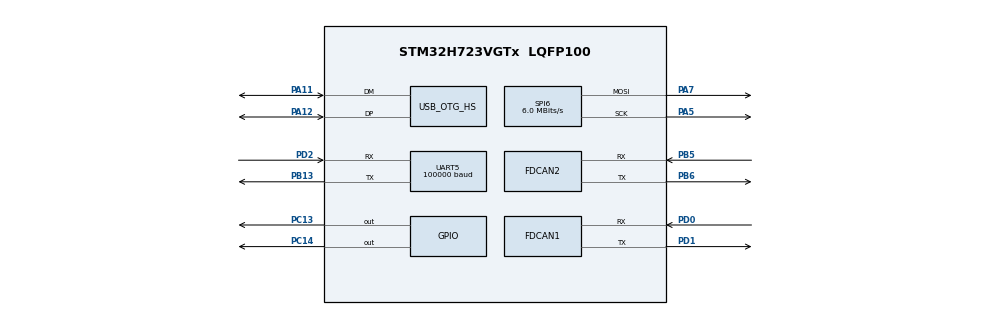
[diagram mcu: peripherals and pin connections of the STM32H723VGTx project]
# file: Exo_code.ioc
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CORTEX_M7.default_mode_Activation=0
Dma.Request0=UART5_RX
Dma.UART5_RX.0.Direction=DMA_PERIPH_TO_MEMORY
Dma.UART5_RX.0.EventEnable=DISABLE
Dma.UART5_RX.0.FIFOMode=DMA_FIFOMODE_DISABLE
Dma.UART5_RX.0.Instance=DMA1_Stream0
Dma.UART5_RX.0.MemDataAlignment=DMA_MDATAALIGN_BYTE
Dma.UART5_RX.0.MemInc=DMA_MINC_ENABLE
Dma.UART5_RX.0.Mode=DMA_CIRCULAR
Dma.UART5_RX.0.PeriphDataAlignment=DMA_PDATAALIGN_BYTE
Dma.UART5_RX.0.PeriphInc=DMA_PINC_DISABLE
Dma.UART5_RX.0.Polarity=HAL_DMAMUX_REQ_GEN_RISING
Dma.UART5_RX.0.Priority=DMA_PRIORITY_VERY_HIGH
Dma.UART5_RX.0.RequestNumber=1
Dma.UART5_RX.0.SignalID=NONE
Dma.UART5_RX.0.SyncEnable=DISABLE
Dma.UART5_RX.0.SyncPolarity=HAL_DMAMUX_SYNC_NO_EVENT
Dma.UART5_RX.0.SyncRequestNumber=1
Dma.UART5_RX.0.SyncSignalID=NONE
FDCAN1.CalculateBaudRateNominal=1000000
FDCAN1.CalculateTimeBitNominal=1000
FDCAN1.CalculateTimeQuantumNominal=25.0
FDCAN1.DataPrescaler=3
FDCAN1.DataSyncJumpWidth=10
FDCAN1.DataTimeSeg1=29
FDCAN1.DataTimeSeg2=10
FDCAN1.NominalPrescaler=3
FDCAN1.NominalSyncJumpWidth=10
FDCAN1.NominalTimeSeg1=29
FDCAN1.NominalTimeSeg2=10
FDCAN1.RxFifo0ElmtSize=FDCAN_DATA_BYTES_32
FDCAN1.RxFifo0ElmtsNbr=4
FDCAN1.StdFiltersNbr=1
FDCAN1.TxElmtSize=FDCAN_DATA_BYTES_32
FDCAN1.TxFifoQueueElmtsNbr=3
FDCAN2.CalculateBaudRateNominal=1000000
FDCAN2.CalculateTimeBitNominal=1000
FDCAN2.CalculateTimeQuantumNominal=25.0
FDCAN2.DataPrescaler=3
FDCAN2.DataSyncJumpWidth=10
FDCAN2.DataTimeSeg1=29
FDCAN2.DataTimeSeg2=10
FDCAN2.MessageRAMOffset=1280
FDCAN2.NominalPrescaler=3
FDCAN2.NominalSyncJumpWidth=10
FDCAN2.NominalTimeSeg1=29
FDCAN2.NominalTimeSeg2=10
FDCAN2.RxFifo0ElmtSize=FDCAN_DATA_BYTES_32
FDCAN2.RxFifo0ElmtsNbr=4
FDCAN2.RxFifo1ElmtSize=FDCAN_DATA_BYTES_8
FDCAN2.RxFifo1ElmtsNbr=0
FDCAN2.StdFiltersNbr=1
FDCAN2.TxElmtSize=FDCAN_DATA_BYTES_32
FDCAN2.TxFifoQueueElmtsNbr=3
FREERTOS.Tasks01=NMotor_Task,3,256,Motor_Task,As weak,NULL,Dynamic,NULL,NULL;NExo_Task,3,256,Exo_Task,As weak,NULL,Dynamic,NULL,NULL;NVofa_Task,3,256,Vofa_Task,As weak,NULL,Dynamic,NULL,NULL;NLed_Task,2,256,Led_Task,As weak,NULL,Dynamic,NULL,NULL
Mcu.Family=STM32H7
Mcu.Name=STM32H723VGTx
Mcu.Package=LQFP100
NVIC.DMA1_Stream0_IRQn=true\:5\:0\:false\:false\:true\:true\:false\:true\:true
NVIC.FDCAN1_IT0_IRQn=true\:5\:0\:false\:false\:true\:true\:true\:true\:true
NVIC.FDCAN2_IT0_IRQn=true\:5\:0\:false\:false\:true\:true\:true\:true\:true
NVIC.OTG_HS_IRQn=true\:5\:0\:false\:false\:true\:true\:true\:true\:true
NVIC.PriorityGroup=NVIC_PRIORITYGROUP_4
NVIC.TIM2_IRQn=true\:15\:0\:false\:false\:true\:false\:false\:true\:true
NVIC.TimeBase=TIM2_IRQn
NVIC.TimeBaseIP=TIM2
NVIC.UART5_IRQn=true\:5\:0\:false\:false\:true\:true\:true\:true\:true
PA11.Mode=Device_Only_FS
PA11.Signal=USB_OTG_HS_DM
PA12.Mode=Device_Only_FS
PA12.Signal=USB_OTG_HS_DP
PA13(JTMS/SWDIO).Mode=Serial_Wire
PA13(JTMS/SWDIO).Signal=DEBUG_JTMS-SWDIO
PA14(JTCK/SWCLK).Mode=Serial_Wire
PA14(JTCK/SWCLK).Signal=DEBUG_JTCK-SWCLK
PA5.GPIO_Speed=GPIO_SPEED_FREQ_VERY_HIGH
PA5.Mode=TX_Only_Simplex_Unidirect_Master
PA5.Signal=SPI6_SCK
PA7.GPIO_Speed=GPIO_SPEED_FREQ_VERY_HIGH
PA7.Mode=TX_Only_Simplex_Unidirect_Master
PA7.Signal=SPI6_MOSI
PB13.Mode=Asynchronous
PB13.Signal=UART5_TX
PB5.Mode=FDCAN_Activate
PB5.Signal=FDCAN2_RX
PB6.Mode=FDCAN_Activate
PB6.Signal=FDCAN2_TX
PC13.PinState=GPIO_PIN_SET
PC13.Signal=GPIO_Output
PC14-OSC32_IN.PinState=GPIO_PIN_SET
PC14-OSC32_IN.Signal=GPIO_Output
PD0.Mode=FDCAN_Activate
PD0.Signal=FDCAN1_RX
PD1.Mode=FDCAN_Activate
PD1.Signal=FDCAN1_TX
PD2.Mode=Asynchronous
PD2.Signal=UART5_RX
PH0-OSC_IN.Mode=HSE-External-Oscillator
PH0-OSC_IN.Signal=RCC_OSC_IN
PH1-OSC_OUT.Mode=HSE-External-Oscillator
PH1-OSC_OUT.Signal=RCC_OSC_OUT
ProjectManager.HeapSize=0x2000
ProjectManager.StackSize=0x4000
ProjectManager.TargetToolchain=CMake
RCC.ADCFreq_Value=48375000
RCC.APB1Freq_Value=120000000
RCC.APB2Freq_Value=120000000
RCC.APB3Freq_Value=120000000
RCC.APB4Freq_Value=120000000
RCC.CortexFreq_Value=480000000
RCC.D1PPRE=RCC_APB3_DIV2
RCC.D2PPRE1=RCC_APB1_DIV2
RCC.D2PPRE2=RCC_APB2_DIV2
RCC.D3PPRE=RCC_APB4_DIV2
RCC.DIVM1=2
RCC.DIVN1=40
RCC.DIVP1=1
RCC.DIVQ1=4
RCC.HCLKFreq_Value=240000000
RCC.HPRE=RCC_HCLK_DIV2
RCC.HSE_VALUE=24000000
RCC.PLLFRACN=0
RCC.PLLSourceVirtual=RCC_PLLSOURCE_HSE
RCC.SPI6CLockSelection=RCC_SPI6CLKSOURCE_HSE
RCC.SYSCLKFreq_VALUE=480000000
RCC.SYSCLKSource=RCC_SYSCLKSOURCE_PLLCLK
RCC.USBCLockSelection=RCC_USBCLKSOURCE_HSI48
RCC.USBFreq_Value=48000000
SPI6.BaudRatePrescaler=SPI_BAUDRATEPRESCALER_4
SPI6.CLKPhase=SPI_PHASE_2EDGE
SPI6.CalculateBaudRate=6.0 MBits/s
SPI6.DataSize=SPI_DATASIZE_8BIT
SPI6.Direction=SPI_DIRECTION_2LINES_TXONLY
SPI6.Mode=SPI_MODE_MASTER
SPI6.VirtualType=VM_MASTER
STMicroelectronics.X-CUBE-ALGOBUILD.1.4.0.LibraryCcDSPOoLibraryJjDSPOoLibrary=true
UART5.BaudRate=100000
UART5.Parity=PARITY_EVEN
UART5.StopBits=UART_STOPBITS_2
UART5.WordLength=WORDLENGTH_9B
USB_DEVICE.CLASS_NAME_HS=CDC
USB_DEVICE.VirtualMode=Cdc
USB_DEVICE.VirtualModeHS=Cdc_HS
USB_OTG_HS.VirtualMode-Device_Only_FS=Device_Only_FS
VP_FREERTOS_VS_CMSIS_V1.Mode=CMSIS_V1
VP_MEMORYMAP_VS_MEMORYMAP.Mode=CurAppReg
VP_STMicroelectronics.X-CUBE-ALGOBUILD_VS_DSPOoLibraryJjLibrary_1.4.0_1.4.0.Mode=DSPOoLibraryJjLibrary
VP_SYS_VS_tim2.Mode=TIM2
VP_USB_DEVICE_VS_USB_DEVICE_CDC_HS.Mode=CDC_HS
board=custom

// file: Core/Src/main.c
/* USER CODE BEGIN Header */
/**
  ******************************************************************************
  * @file           : main.c
  * @brief          : Main program body
  ******************************************************************************
  * @attention
  *
  * Copyright (c) 2026 STMicroelectronics.
  * All rights reserved.
  *
  * This software is licensed under terms that can be found in the LICENSE file
  * in the root directory of this software component.
  * If no LICENSE file comes with this software, it is provided AS-IS.
  *
  ******************************************************************************
  */
/* USER CODE END Header */
#include "main.h"
#include "cmsis_os.h"
#include "dma.h"
#include "fdcan.h"
#include "spi.h"
#include "usart.h"
#include "usb_device.h"
#include "gpio.h"

/* USER CODE BEGIN Includes */
#include "motor_can.h"
#include "vofa.h"
/* USER CODE END Includes */

void SystemClock_Config(void);
void MX_FREERTOS_Init(void);

int main(void)
{

  /* MCU Configuration--------------------------------------------------------*/

  /* Reset of all peripherals, Initializes the Flash interface and the Systick. */
  HAL_Init();

  /* Configure the system clock */
  SystemClock_Config();

  /* Initialize all configured peripherals */
  MX_GPIO_Init();
  MX_DMA_Init();
  MX_UART5_Init();
  MX_FDCAN1_Init();
  MX_FDCAN2_Init();
  MX_SPI6_Init();
  /* USER CODE BEGIN 2 */
  MX_USB_DEVICE_Init();
  HAL_Delay(2000);
  MotorCAN_Init();
  MotorCAN_Enable(MOTOR_ID_LEFT);
  MotorCAN_Enable(MOTOR_ID_RIGHT);
  /* USER CODE END 2 */

  /* Call init function for freertos objects (in cmsis_os2.c) */
  MX_FREERTOS_Init();

  /* Start scheduler */
  osKernelStart();

  /* We should never get here as control is now taken by the scheduler */

  /* Infinite loop */
  while (1)
  {

  }
}

void SystemClock_Config(void)
{
  RCC_OscInitTypeDef RCC_OscInitStruct = {0};
  RCC_ClkInitTypeDef RCC_ClkInitStruct = {0};

  /** Supply configuration update enable
  */
  HAL_PWREx_ConfigSupply(PWR_LDO_SUPPLY);

  /** Configure the main internal regulator output voltage
  */
  __HAL_PWR_VOLTAGESCALING_CONFIG(PWR_REGULATOR_VOLTAGE_SCALE0);

  while(!__HAL_PWR_GET_FLAG(PWR_FLAG_VOSRDY)) {}

  /** Initializes the RCC Oscillators according to the specified parameters
  * in the RCC_OscInitTypeDef structure.
  */
  RCC_OscInitStruct.OscillatorType = RCC_OSCILLATORTYPE_HSI48|RCC_OSCILLATORTYPE_HSE;
  RCC_OscInitStruct.HSEState = RCC_HSE_ON;
  RCC_OscInitStruct.HSI48State = RCC_HSI48_ON;
  RCC_OscInitStruct.PLL.PLLState = RCC_PLL_ON;
  RCC_OscInitStruct.PLL.PLLSource = RCC_PLLSOURCE_HSE;
  RCC_OscInitStruct.PLL.PLLM = 2;
  RCC_OscInitStruct.PLL.PLLN = 40;
  RCC_OscInitStruct.PLL.PLLP = 1;
  RCC_OscInitStruct.PLL.PLLQ = 4;
  RCC_OscInitStruct.PLL.PLLR = 2;
  RCC_OscInitStruct.PLL.PLLRGE = RCC_PLL1VCIRANGE_3;
  RCC_OscInitStruct.PLL.PLLVCOSEL = RCC_PLL1VCOWIDE;
  RCC_OscInitStruct.PLL.PLLFRACN = 0;
  if (HAL_RCC_OscConfig(&RCC_OscInitStruct) != HAL_OK)
  {
    Error_Handler();
  }

  /** Initializes the CPU, AHB and APB buses clocks
  */
  RCC_ClkInitStruct.ClockType = RCC_CLOCKTYPE_HCLK|RCC_CLOCKTYPE_SYSCLK
                              |RCC_CLOCKTYPE_PCLK1|RCC_CLOCKTYPE_PCLK2
                              |RCC_CLOCKTYPE_D3PCLK1|RCC_CLOCKTYPE_D1PCLK1;
  RCC_ClkInitStruct.SYSCLKSource = RCC_SYSCLKSOURCE_PLLCLK;
  RCC_ClkInitStruct.SYSCLKDivider = RCC_SYSCLK_DIV1;
  RCC_ClkInitStruct.AHBCLKDivider = RCC_HCLK_DIV2;
  RCC_ClkInitStruct.APB3CLKDivider = RCC_APB3_DIV2;
  RCC_ClkInitStruct.APB1CLKDivider = RCC_APB1_DIV2;
  RCC_ClkInitStruct.APB2CLKDivider = RCC_APB2_DIV2;
  RCC_ClkInitStruct.APB4CLKDivider = RCC_APB4_DIV2;

  if (HAL_RCC_ClockConfig(&RCC_ClkInitStruct, FLASH_LATENCY_3) != HAL_OK)
  {
    Error_Handler();
  }
}

void HAL_TIM_PeriodElapsedCallback(TIM_HandleTypeDef *htim)
{
  if (htim->Instance == TIM2) {
    HAL_IncTick();
  }
}

void Error_Handler(void)
{
  __disable_irq();
  while (1)
  {
  }
}

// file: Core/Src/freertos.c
/* USER CODE BEGIN Header */
/**
  ******************************************************************************
  * File Name          : freertos.c
  * Description        : Code for freertos applications
  ******************************************************************************
  * @attention
  *
  * Copyright (c) 2026 STMicroelectronics.
  * All rights reserved.
  *
  * This software is licensed under terms that can be found in the LICENSE file
  * in the root directory of this software component.
  * If no LICENSE file comes with this software, it is provided AS-IS.
  *
  ******************************************************************************
  */
/* USER CODE END Header */

#include "FreeRTOS.h"
#include "task.h"
#include "main.h"
#include "cmsis_os.h"

osThreadId NMotor_TaskHandle;
osThreadId NExo_TaskHandle;
osThreadId NVofa_TaskHandle;
osThreadId NLed_TaskHandle;

void Motor_Task(void const * argument);
void Exo_Task(void const * argument);
void Vofa_Task(void const * argument);
void Led_Task(void const * argument);

extern void MX_USB_DEVICE_Init(void);
void MX_FREERTOS_Init(void); /* (MISRA C 2004 rule 8.1) */

/* GetIdleTaskMemory prototype (linked to static allocation support) */
void vApplicationGetIdleTaskMemory( StaticTask_t **ppxIdleTaskTCBBuffer, StackType_t **ppxIdleTaskStackBuffer, uint32_t *pulIdleTaskStackSize );

/* USER CODE BEGIN GET_IDLE_TASK_MEMORY */
static StaticTask_t xIdleTaskTCBBuffer;
static StackType_t xIdleStack[configMINIMAL_STACK_SIZE];

void vApplicationGetIdleTaskMemory( StaticTask_t **ppxIdleTaskTCBBuffer, StackType_t **ppxIdleTaskStackBuffer, uint32_t *pulIdleTaskStackSize )
{
  *ppxIdleTaskTCBBuffer = &xIdleTaskTCBBuffer;
  *ppxIdleTaskStackBuffer = &xIdleStack[0];
  *pulIdleTaskStackSize = configMINIMAL_STACK_SIZE;
  /* place for user code */
}
/* USER CODE END GET_IDLE_TASK_MEMORY */

void MX_FREERTOS_Init(void) {

  /* Create the thread(s) */
  /* definition and creation of NMotor_Task */
  osThreadDef(NMotor_Task, Motor_Task, osPriorityRealtime, 0, 256);
  NMotor_TaskHandle = osThreadCreate(osThread(NMotor_Task), NULL);

  /* definition and creation of NExo_Task */
  osThreadDef(NExo_Task, Exo_Task, osPriorityRealtime, 0, 256);
  NExo_TaskHandle = osThreadCreate(osThread(NExo_Task), NULL);

  /* definition and creation of NVofa_Task */
  osThreadDef(NVofa_Task, Vofa_Task, osPriorityRealtime, 0, 256);
  NVofa_TaskHandle = osThreadCreate(osThread(NVofa_Task), NULL);

  /* definition and creation of NLed_Task */
  osThreadDef(NLed_Task, Led_Task, osPriorityHigh, 0, 256);
  NLed_TaskHandle = osThreadCreate(osThread(NLed_Task), NULL);

}

__weak void Motor_Task(void const * argument)
{
  /* init code for USB_DEVICE */
  MX_USB_DEVICE_Init();
  for(;;)
  {
    osDelay(1);
  }
}

__weak void Exo_Task(void const * argument)
{
  for(;;)
  {
    osDelay(1);
  }
}

__weak void Vofa_Task(void const * argument)
{
  for(;;)
  {
    osDelay(1);
  }
}

__weak void Led_Task(void const * argument)
{
  for(;;)
  {
    osDelay(1);
  }
}
